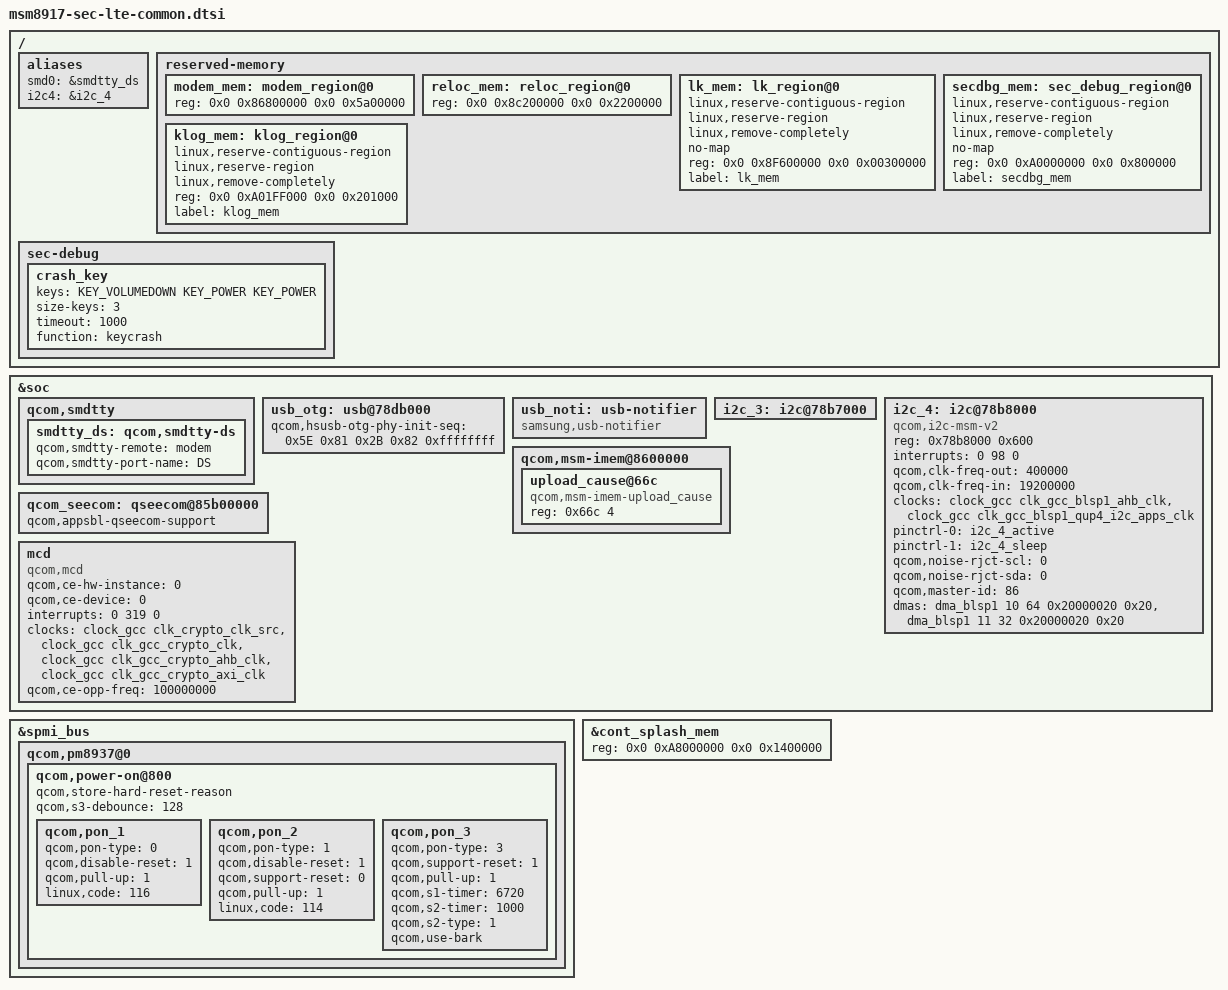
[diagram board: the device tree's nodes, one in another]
/*
 * Copyright (c) 2015, The Linux Foundation. All rights reserved.
 *
 * This program is free software; you can redistribute it and/or modify
 * it under the terms of the GNU General Public License version 2 and
 * only version 2 as published by the Free Software Foundation.
 *
 * This program is distributed in the hope that it will be useful,
 * but WITHOUT ANY WARRANTY; without even the implied warranty of
 * MERCHANTABILITY or FITNESS FOR A PARTICULAR PURPOSE.  See the
 * GNU General Public License for more details.
 */

#include <dt-bindings/input/input.h>

/ {
	aliases {
		smd0 = &smdtty_ds;

		/delete-property/ i2c4;
		i2c4 = &i2c_4;
	};
};

&soc {
	qcom,smdtty {
		smdtty_ds: qcom,smdtty-ds {
			qcom,smdtty-remote = "modem";
			qcom,smdtty-port-name = "DS";
		};

	};

	/delete-node/ smbcharger_charger_otg;

	usb_otg: usb@78db000 {
		/delete-property/ vbus_otg-supply;
	};

	usb_noti: usb-notifier {
		compatible = "samsung,usb-notifier";
	};

	i2c_3: i2c@78b7000 {
		/delete-property/ status;
	};

	i2c_4: i2c@78b8000 { /* BLSP1 QUP4 */
		compatible = "qcom,i2c-msm-v2";
		#address-cells = <1>;
		#size-cells = <0>;
		reg-names = "qup_phys_addr";
		reg = <0x78b8000 0x600>;
		interrupt-names = "qup_irq";
		interrupts = <0 98 0>;
		qcom,clk-freq-out = <400000>;
		qcom,clk-freq-in  = <19200000>;
		clock-names = "iface_clk", "core_clk";
		clocks = <&clock_gcc clk_gcc_blsp1_ahb_clk>,
			<&clock_gcc clk_gcc_blsp1_qup4_i2c_apps_clk>;

		pinctrl-names = "i2c_active", "i2c_sleep";
		pinctrl-0 = <&i2c_4_active>;
		pinctrl-1 = <&i2c_4_sleep>;
		qcom,noise-rjct-scl = <0>;
		qcom,noise-rjct-sda = <0>;
		qcom,master-id = <86>;
		dmas = <&dma_blsp1 10 64 0x20000020 0x20>,
			<&dma_blsp1 11 32 0x20000020 0x20>;
		dma-names = "tx", "rx";
	};

	qcom,msm-imem@8600000 {
                upload_cause@66c {
                        compatible = "qcom,msm-imem-upload_cause";
                        reg = <0x66c 4>;
                };
        };

	qcom_seecom: qseecom@85b00000 {
		qcom,appsbl-qseecom-support;
	};

	mcd: mcd {
		compatible = "qcom,mcd";
		qcom,ce-hw-instance = <0>;
		qcom,ce-device = <0>;
		interrupts = <0 319 0>;
		interrupt-names = "mcd_irq";
		clocks = <&clock_gcc clk_crypto_clk_src>,
			 <&clock_gcc clk_gcc_crypto_clk>,
			 <&clock_gcc clk_gcc_crypto_ahb_clk>,
			 <&clock_gcc clk_gcc_crypto_axi_clk>;
		clock-names = "core_clk_src", "core_clk",
				"iface_clk", "bus_clk";
		qcom,ce-opp-freq = <100000000>;
	};
};

/ {
	reserved-memory {
		modem_mem: modem_region@0 {
			reg = <0x0 0x86800000 0x0 0x5a00000>;
		};

		reloc_mem: reloc_region@0 {
			reg = <0x0 0x8c200000 0x0 0x2200000>;
		};

		lk_mem: lk_region@0 {
			linux,reserve-contiguous-region;
			linux,reserve-region;
			linux,remove-completely;
			no-map;
			reg = <0x0 0x8F600000 0x0 0x00300000>;
			label = "lk_mem";
		};
		
		secdbg_mem: sec_debug_region@0 {
			linux,reserve-contiguous-region;
			linux,reserve-region;
			linux,remove-completely;
			no-map;
			reg = <0x0 0xA0000000 0x0 0x800000>;
			label = "secdbg_mem";
		};
		
		klog_mem: klog_region@0 {
			linux,reserve-contiguous-region;
			linux,reserve-region;
			linux,remove-completely;
			reg = <0x0 0xA01FF000 0x0 0x201000>;
			label = "klog_mem";
		}; 
	};

	sec-debug {
		crash_key {
			keys = <KEY_VOLUMEDOWN KEY_POWER KEY_POWER>;
			size-keys = <3>;
			timeout = <1000>;	/* default = 1000msec */
			function = "keycrash";
		};

		/* tsp_dump {
			keys = <KEY_VOLUMEUP KEY_HOMEPAGE KEY_HOMEPAGE>;
			size-keys = <3>;
			timeout = <1000>;
			function = "tsp_dump";
		}; */
	};

};

&spmi_bus {
	qcom,pm8937@0 {
		qcom,power-on@800 {
			qcom,store-hard-reset-reason;

			qcom,s3-debounce = <128>;
			qcom,pon_1 {
				qcom,pon-type = <0>;
				qcom,disable-reset = <1>;
				qcom,pull-up = <1>;
				linux,code = <116>;
			};

			qcom,pon_2 {
				qcom,pon-type = <1>;
				qcom,disable-reset = <1>;
				qcom,support-reset = <0>;
				qcom,pull-up = <1>;
				linux,code = <114>;
			};

			qcom,pon_3 {
				qcom,pon-type = <3>;
				qcom,support-reset = <1>;
				qcom,pull-up = <1>;
				qcom,s1-timer = <6720>;
				qcom,s2-timer = <1000>;
				qcom,s2-type = <1>;
				qcom,use-bark;
			};
		};
	};
};

&cont_splash_mem {
	reg = <0x0 0xA8000000 0x0 0x1400000>;
};

&usb_otg {
	qcom,hsusb-otg-phy-init-seq = 
					<0x5E 0x81 0x2B 0x82 0xffffffff>;
};
